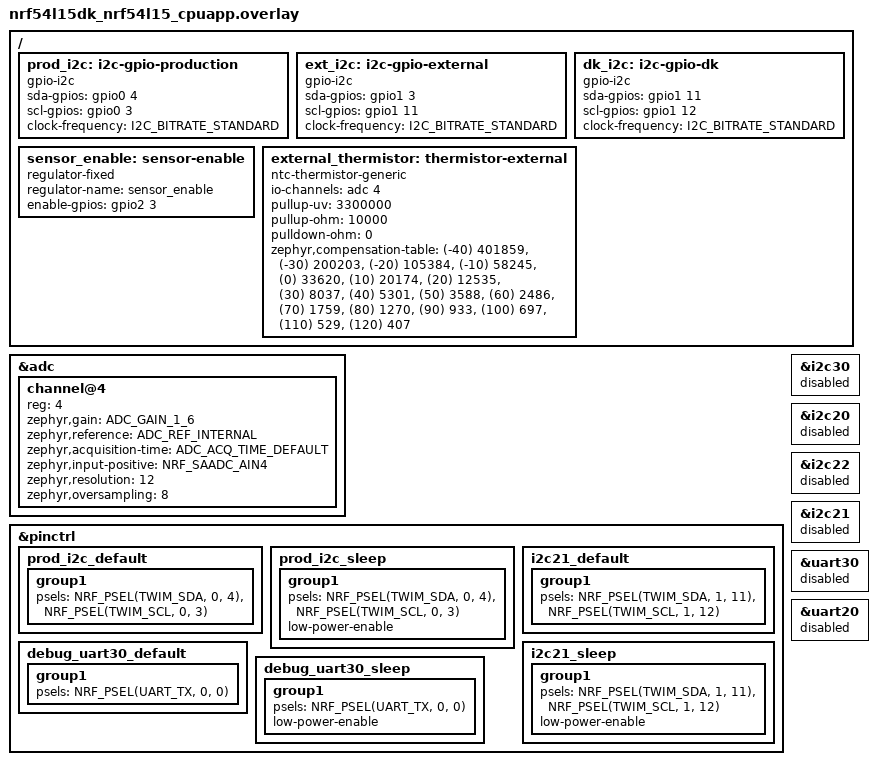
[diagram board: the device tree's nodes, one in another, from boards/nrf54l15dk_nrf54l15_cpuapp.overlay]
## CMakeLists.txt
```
# SPDX-License-Identifier: Apache-2.0

cmake_minimum_required(VERSION 3.20.0)
find_package(Zephyr REQUIRED HINTS $ENV{ZEPHYR_BASE})
project(blinky)

target_sources(app PRIVATE src/main.c)
target_sources(app PRIVATE src/sentry_auth.c)
target_sources(app PRIVATE src/serial30_mux.c)
target_sources_ifdef(CONFIG_BT_RAS_RRSP app PRIVATE src/cs_reflector.c)
```

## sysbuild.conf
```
# Build MCUboot alongside SS1 and create primary/secondary image slots.
SB_CONFIG_BOOTLOADER_MCUBOOT=y
SB_CONFIG_BOOT_SIGNATURE_TYPE_ECDSA_P256=y

# Production signing key. The private key is intentionally gitignored and
# must be provisioned locally/through CI before a production build.
SB_CONFIG_BOOT_SIGNATURE_KEY_FILE="\${APPLICATION_CONFIG_DIR}/keys/ss1_mcuboot_prod_key.pem"
```

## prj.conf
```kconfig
CONFIG_GPIO=y
CONFIG_SENSOR=y

CONFIG_BT=y
CONFIG_BT_PERIPHERAL=y
CONFIG_BT_DEVICE_NAME="Joseph_BLE"
CONFIG_HWINFO=y

# Allow up to 3 simultaneous BLE connections
CONFIG_BT_MAX_CONN=3

CONFIG_PRINTK=y
CONFIG_SERIAL=y
CONFIG_CONSOLE=n
CONFIG_UART_CONSOLE=n
CONFIG_STDOUT_CONSOLE=n
CONFIG_REBOOT=y
CONFIG_NRFX_UARTE=y
CONFIG_NRFX_TWIM=y

# Bluetooth-standard security
CONFIG_BT_SMP=y
CONFIG_BT_BONDABLE=y
CONFIG_BT_MAX_PAIRED=3
CONFIG_BT_KEYS_OVERWRITE_OLDEST=y
CONFIG_BT_GATT_AUTO_SEC_REQ=n

# Let the app accept/reject incoming pairing requests
CONFIG_BT_SMP_APP_PAIRING_ACCEPT=y

# Settings/NVS retain the encryption bond; certificate auth still uses a
# fresh nonce on every connection.
CONFIG_BT_SETTINGS=y
CONFIG_SETTINGS=y
CONFIG_FLASH=y
CONFIG_FLASH_MAP=y
CONFIG_NVS=y

CONFIG_I2C=y
CONFIG_I2C_NRFX=y
CONFIG_I2C_GPIO=y
CONFIG_I2C_GPIO_CLOCK_STRETCHING=y
CONFIG_ADC=y
CONFIG_NTC_THERMISTOR=y

# PSA crypto (nRF54L15 CRACEN). NRF_SECURITY is selected automatically.
CONFIG_NRF_OBERON=y
CONFIG_PSA_WANT_ALG_ECDSA=y
CONFIG_PSA_WANT_ALG_SHA_256=y
CONFIG_PSA_WANT_ECC_SECP_R1_256=y
CONFIG_PSA_WANT_KEY_TYPE_ECC_PUBLIC_KEY=y
CONFIG_PSA_WANT_GENERATE_RANDOM=y

# Bigger ATT MTU so the 204-byte auth response fits in one write.
CONFIG_BT_L2CAP_TX_MTU=247
CONFIG_BT_BUF_ACL_TX_SIZE=251
CONFIG_BT_BUF_ACL_RX_SIZE=251

# SS1 supports three links and RAS can leave several ATT packets queued while
# a departed link is being torn down. Keep response headroom so a replacement
# link can always answer its MTU exchange instead of silently timing out.
CONFIG_BT_ATT_TX_COUNT=12
CONFIG_BT_L2CAP_TX_BUF_COUNT=12
CONFIG_BT_BUF_ACL_TX_COUNT=6

# --- Channel Sounding: RAS Reflector role ---
CONFIG_BT_CTLR_PHY_2M=y
CONFIG_BT_CTLR_DATA_LENGTH_MAX=251
CONFIG_BT_TRANSMIT_POWER_CONTROL=y

# Single-antenna, mode-3-disabled profile (matches Blonky's initiator config)
CONFIG_BT_RAS_MODE_3_SUPPORTED=n
CONFIG_BT_RAS_MAX_ANTENNA_PATHS=1
CONFIG_BT_CTLR_SDC_CS_MAX_ANTENNA_PATHS=1
CONFIG_BT_CTLR_SDC_CS_NUM_ANTENNAS=1
CONFIG_BT_CTLR_SDC_CS_STEP_MODE3=n
CONFIG_BT_CTLR_SDC_CS_ROLE_REFLECTOR_ONLY=y
CONFIG_BT_CTLR_CHANNEL_SOUNDING_TEST=n

CONFIG_BT_CHANNEL_SOUNDING=y
CONFIG_BT_RAS=y
CONFIG_BT_RAS_RRSP=y

# MCUboot + MCUmgr/SMP firmware updates over BLE. Only the image and OS
# management groups are enabled; shell, filesystem and settings erase are not.
CONFIG_BOOTLOADER_MCUBOOT=y
# Keep application-side imgtool metadata aligned with the ECDSA-P256 MCUboot
# child image. ECDSA-P256 selects SHA-256 in MCUboot, so imgtool must emit the
# corresponding SHA-256 image hash TLV.
CONFIG_MCUBOOT_BOOTLOADER_SIGNATURE_TYPE_ED25519=n
CONFIG_MCUBOOT_BOOTLOADER_USES_SHA512=n
CONFIG_MCUBOOT_BOOTLOADER_NO_DOWNGRADE=y
CONFIG_NET_BUF=y
CONFIG_ZCBOR=y
CONFIG_CRC=y
CONFIG_STREAM_FLASH=y
CONFIG_IMG_MANAGER=y
CONFIG_MCUMGR=y
CONFIG_MCUMGR_GRP_IMG=y
CONFIG_MCUMGR_GRP_OS=y
CONFIG_MCUMGR_TRANSPORT_BT=y
# Lab/test transport: image authenticity is still enforced by MCUboot's
# signature. Replace this with an authenticated OTA gate before deployment.
CONFIG_MCUMGR_TRANSPORT_BT_PERM_RW=y
CONFIG_BT_GATT_AUTHORIZATION_CUSTOM=y
CONFIG_MCUMGR_TRANSPORT_BT_CONN_PARAM_CONTROL=y
CONFIG_MCUMGR_TRANSPORT_BT_REASSEMBLY=y
CONFIG_MCUMGR_TRANSPORT_NETBUF_SIZE=1220
CONFIG_MCUMGR_GRP_OS_MCUMGR_PARAMS=y
CONFIG_MCUMGR_TRANSPORT_WORKQUEUE_STACK_SIZE=4608
```

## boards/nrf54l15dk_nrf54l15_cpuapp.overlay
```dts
/*
 * The production PCB places both debug TX and the sensor on P0. UART30 and
 * TWIM30 are the same SERIAL30 block, so keep the reliable hardware UART and
 * use Zephyr's GPIO I2C controller for the low-rate SHT41 bus.
 */
/ {
	prod_i2c: i2c-gpio-production {
		compatible = "gpio-i2c";
		status = "okay";
		#address-cells = <1>;
		#size-cells = <0>;
		sda-gpios = <&gpio0 4 (GPIO_OPEN_DRAIN | GPIO_PULL_UP)>;
		scl-gpios = <&gpio0 3 (GPIO_OPEN_DRAIN | GPIO_PULL_UP)>;
		clock-frequency = <I2C_BITRATE_STANDARD>;
	};

	ext_i2c: i2c-gpio-external {
		compatible = "gpio-i2c";
		status = "okay";
		#address-cells = <1>;
		#size-cells = <0>;
		sda-gpios = <&gpio1 3 (GPIO_OPEN_DRAIN | GPIO_PULL_UP)>;
		scl-gpios = <&gpio1 11 (GPIO_OPEN_DRAIN | GPIO_PULL_UP)>;
		clock-frequency = <I2C_BITRATE_STANDARD>;
	};

	/* GPIO implementation avoids a static TWIM21 claim on P1.11, which is
	 * also the external connector's SCL/thermistor ADC signal. */
	dk_i2c: i2c-gpio-dk {
		compatible = "gpio-i2c";
		status = "okay";
		#address-cells = <1>;
		#size-cells = <0>;
		sda-gpios = <&gpio1 11 (GPIO_OPEN_DRAIN | GPIO_PULL_UP)>;
		scl-gpios = <&gpio1 12 (GPIO_OPEN_DRAIN | GPIO_PULL_UP)>;
		clock-frequency = <I2C_BITRATE_STANDARD>;
	};

	/* Production SS1 switched sensor rail, active-high on P2.03. */
	sensor_enable: sensor-enable {
		compatible = "regulator-fixed";
		regulator-name = "sensor_enable";
		enable-gpios = <&gpio2 3 GPIO_ACTIVE_HIGH>;
	};

	/*
	 * Optional external 10 kOhm/B3950 NTC. The PCB's 10 kOhm pull-up is
	 * already connected to EX_SCL_THERM2 (P1.11/AIN4); the attachment puts
	 * the thermistor between that signal and ground.
	 */
	external_thermistor: thermistor-external {
		compatible = "ntc-thermistor-generic";
		status = "okay";
		io-channels = <&adc 4>;
		pullup-uv = <3300000>;
		pullup-ohm = <10000>;
		pulldown-ohm = <0>;
		zephyr,compensation-table = <(-40) 401859>,
			<(-30) 200203>,
			<(-20) 105384>,
			<(-10) 58245>,
			<(0) 33620>,
			<(10) 20174>,
			<(20) 12535>,
			<(30) 8037>,
			<(40) 5301>,
			<(50) 3588>,
			<(60) 2486>,
			<(70) 1759>,
			<(80) 1270>,
			<(90) 933>,
			<(100) 697>,
			<(110) 529>,
			<(120) 407>;
	};

};

&adc {
	status = "okay";
	#address-cells = <1>;
	#size-cells = <0>;

	channel@4 {
		reg = <4>;
		zephyr,gain = "ADC_GAIN_1_6";
		zephyr,reference = "ADC_REF_INTERNAL";
		zephyr,acquisition-time = <ADC_ACQ_TIME_DEFAULT>;
		zephyr,input-positive = <NRF_SAADC_AIN4>; /* P1.11 */
		zephyr,resolution = <12>;
		zephyr,oversampling = <8>;
	};
};

&pinctrl {
	prod_i2c_default: prod_i2c_default {
		group1 {
			psels = <NRF_PSEL(TWIM_SDA, 0, 4)>,
				<NRF_PSEL(TWIM_SCL, 0, 3)>;
		};
	};

	prod_i2c_sleep: prod_i2c_sleep {
		group1 {
			psels = <NRF_PSEL(TWIM_SDA, 0, 4)>,
				<NRF_PSEL(TWIM_SCL, 0, 3)>;
			low-power-enable;
		};
	};

	i2c21_default: i2c21_default {
		group1 {
			psels = <NRF_PSEL(TWIM_SDA, 1, 11)>,
				<NRF_PSEL(TWIM_SCL, 1, 12)>;
		};
	};

	i2c21_sleep: i2c21_sleep {
		group1 {
			psels = <NRF_PSEL(TWIM_SDA, 1, 11)>,
				<NRF_PSEL(TWIM_SCL, 1, 12)>;
			low-power-enable;
		};
	};

	debug_uart30_default: debug_uart30_default {
		group1 {
			psels = <NRF_PSEL(UART_TX, 0, 0)>;
		};
	};

	debug_uart30_sleep: debug_uart30_sleep {
		group1 {
			psels = <NRF_PSEL(UART_TX, 0, 0)>;
			low-power-enable;
		};
	};

};

/*
 * Production SS1 I2C: SDA P0.04, SCL P0.03.
 *
 * TWIM20/21/22 are physically restricted to GPIO port P1 on nRF54L15.
 * TWIM30 is the hardware controller that can reach GPIO port P0.
 */
&i2c30 {
	status = "disabled";
};

&i2c20 {
	status = "disabled";
};

&i2c22 {
	status = "disabled";
};

/* DK I2C: SDA P1.11, SCL P1.12. */
&i2c21 {
	status = "disabled";
};

&uart30 {
	status = "disabled";
};

&uart20 {
	status = "disabled";
};
```

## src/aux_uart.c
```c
/*
 * SPDX-License-Identifier: Apache-2.0
 */

#include <stdbool.h>
#include <stddef.h>
#include <stdint.h>
#include <string.h>

#include <zephyr/device.h>
#include <zephyr/drivers/uart.h>
#include <zephyr/sys/printk.h>
#include <zephyr/sys/util.h>
#include <zephyr/bluetooth/bluetooth.h>
#include <zephyr/bluetooth/addr.h>

#include "aux_uart.h"

#define AUX_UART_NODE DT_NODELABEL(uart30)

#define AUX_PAN_LEN  4
#define AUX_ID_LEN   2
#define AUX_MSG_LEN  9   /* both TSSA... and HSSA... messages are 9 chars */

static const struct device *aux_uart_dev = DEVICE_DT_GET(AUX_UART_NODE);
static bool aux_uart_ready;

static char aux_pan_id[AUX_PAN_LEN + 1] = "0000";
static char aux_unit_id[AUX_ID_LEN + 1] = "00";

static uint8_t aux_seq;

static const char aux_status_msg[AUX_MSG_LEN] = {
	'S', 'S', '3', '6', '1', '#', 'H', '1', 'W',
};

static void aux_uart_write(const char *buf, size_t len)
{
	for (size_t i = 0; i < len; i++) {
		uart_poll_out(aux_uart_dev, buf[i]);
	}
}

void aux_uart_init_check(void)
{
	if (!device_is_ready(aux_uart_dev)) {
		aux_uart_ready = false;
		printk("AUX UART (uart30) is not ready. Packet output disabled.\n");
		return;
	}

	aux_uart_ready = true;

	printk("AUX UART ready: %s (P0.00 TX / P0.01 RX / P0.02 RTS / P0.03 CTS)\n",
	       aux_uart_dev->name);
}

void aux_uart_load_identity(void)
{
	bt_addr_le_t addrs[CONFIG_BT_ID_MAX];
	size_t count = ARRAY_SIZE(addrs);
	char hex[2 * 6 + 1];

	bt_id_get(addrs, &count);

	if (count == 0) {
		printk("AUX UART: no BT identity address yet - keeping placeholder PAN=%s ID=%s\n",
		       aux_pan_id, aux_unit_id);
		return;
	}

	/*
	 * bt_addr_le_t stores the 6-byte MAC little-endian (val[0] = LSB).
	 * Rebuild it MSB-first (the order a MAC is conventionally written
	 * in, e.g. as bt_addr_le_to_str prints it) before slicing hex
	 * characters out of it. This is the genuine identity address -
	 * bt_id_get() returns it even when LE Privacy is enabled and a
	 * rotating RPA is what's actually broadcast over the air.
	 */
	snprintk(hex, sizeof(hex), "%02X%02X%02X%02X%02X%02X",
		 addrs[0].a.val[5], addrs[0].a.val[4], addrs[0].a.val[3],
		 addrs[0].a.val[2], addrs[0].a.val[1], addrs[0].a.val[0]);

	memcpy(aux_pan_id, hex, AUX_PAN_LEN);
	aux_pan_id[AUX_PAN_LEN] = '\0';
	memcpy(aux_unit_id, hex + AUX_PAN_LEN, AUX_ID_LEN);
	aux_unit_id[AUX_ID_LEN] = '\0';

	printk("AUX UART packet identity: PAN=%s ID=%s (from BT MAC %s)\n",
	       aux_pan_id, aux_unit_id, hex);
}

/* "TSSA" <sign> <tens><units> '.' <decimal> -> 9 chars, no NUL. */
static void format_temp_msg(char out[AUX_MSG_LEN], int16_t temp_cdeg)
{
	int32_t temp_deci = (temp_cdeg >= 0) ? (temp_cdeg + 5) / 10 : (temp_cdeg - 5) / 10;
	char sign = (temp_deci < 0) ? '-' : '+';
	int32_t whole = (temp_deci < 0) ? -temp_deci : temp_deci;
	int32_t frac = whole % 10;

	whole /= 10;
	if (whole > 99) {
		whole = 99; /* saturate: format is fixed at 2 digits */
	}

	snprintk(out, AUX_MSG_LEN + 1, "TSSA%c%02d.%d", sign, (int)whole, (int)frac);
}

/* "HSSA" <tens><units> '.' <decimal> <pad '-'> -> 9 chars, no NUL, no sign. */
static void format_hum_msg(char out[AUX_MSG_LEN], uint16_t hum_cpercent)
{
	uint32_t deci = (hum_cpercent + 5) / 10;
	int32_t frac = deci % 10;
	int32_t whole = deci / 10;
	int len;

	if (whole > 99) {
		whole = 99;
	}

	len = snprintk(out, AUX_MSG_LEN, "HSSA%02d.%d", (int)whole, (int)frac);
	while (len < AUX_MSG_LEN) {
		out[len++] = '-';
	}
}

/*
 * m <PAN><ID> d <data...> r -<RSSI 000> s <seq 3 digits> CR
 * CR (0x0D) only - no trailing LF, per the reference packet format.
 */
/* Envelope overhead (everything except the data section):
 * 'm' + PAN(4) + ID(2) + 'd' + 'r' + '-' + RSSI(3) + 's' + seq(3) + CR(1) = 19
 */
#define AUX_PACKET_OVERHEAD 19

static void send_packet(const char *data, size_t data_len)
{
	char pkt[AUX_PACKET_OVERHEAD + AUX_MSG_LEN];
	size_t len = 0;

	pkt[len++] = 'm';
	memcpy(&pkt[len], aux_pan_id, AUX_PAN_LEN);
	len += AUX_PAN_LEN;
	memcpy(&pkt[len], aux_unit_id, AUX_ID_LEN);
	len += AUX_ID_LEN;
	pkt[len++] = 'd';
	memcpy(&pkt[len], data, data_len);
	len += data_len;
	pkt[len++] = 'r';
	pkt[len++] = '-';
	memcpy(&pkt[len], "000", 3);
	len += 3;
	pkt[len++] = 's';
	pkt[len++] = '0' + (aux_seq / 100) % 10;
	pkt[len++] = '0' + (aux_seq / 10) % 10;
	pkt[len++] = '0' + (aux_seq % 10);
	pkt[len++] = '\r';

	aux_uart_write(pkt, len);
}

static void advance_sequence(void)
{
	aux_seq++;

	if (aux_seq == 0) {
		/* Rolled over 255 -> 0: send the status message using the
		 * wrapped value, then move past it before normal data resumes.
		 */
		send_packet(aux_status_msg, AUX_MSG_LEN);
		aux_seq++;
	}
}

void aux_uart_send_temp_humidity(int16_t temp_cdeg, uint16_t hum_cpercent)
{
	char msg[AUX_MSG_LEN];

	if (!aux_uart_ready) {
		return;
	}

	/* One packet per value - each is its own transmission and consumes
	 * its own sequence number. */
	format_temp_msg(msg, temp_cdeg);
	send_packet(msg, AUX_MSG_LEN);
	advance_sequence();

	format_hum_msg(msg, hum_cpercent);
	send_packet(msg, AUX_MSG_LEN);
	advance_sequence();
}
```

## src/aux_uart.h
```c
/*
 * SPDX-License-Identifier: Apache-2.0
 *
 * Auxiliary UART (uart30) - wired sensor-bridge packet output.
 *
 * UART instance on P0.00(TX)/P0.01(RX)/P0.02(RTS)/P0.03(CTS). On the
 * production board it is shared with the printk/debug console because this
 * is the only exposed serial output. Feeds a TTL serial converter, not SS2.
 *
 * Implements the reference "sensor bridge unit" packet format:
 *   m <PAN 4ch> <unit ID 2ch> d <data> r -<RSSI 3ch> s <seq 3ch> CR
 * with per-reading messages:
 *   Temperature: "TSSA" <sign> <tens><units> '.' <decimal>       (9 chars)
 *   Humidity:    "HSSA" <tens><units> '.' <decimal> <pad '-'>    (9 chars)
 * One packet per value: a temperature reading and a humidity reading are
 * sent as two separate packets, each with its own sequence number. RSSI is
 * always "000" (wired, no radio). The sequence counter is a rolling 1-byte
 * counter, shared across both packet types; on wraparound (255 -> 0) a
 * status message ("SS361#H1W", hardware char 'W' = wired sensor) is sent
 * using the wrapped value before normal data resumes.
 *
 * PAN ID / unit ID are derived from this device's real BLE identity
 * address (via bt_id_get(), which always returns the genuine, fixed
 * address - not a rotating LE Privacy/RPA address): the first 4 hex
 * characters of the MAC (in conventional MSB-first display order) become
 * the PAN ID, the next 2 become the unit ID.
 */

#ifndef AUX_UART_H_
#define AUX_UART_H_

#include <stdint.h>

/* Call once from main(), alongside sht3x_init_check(). Readies the uart30
 * device only; does not touch BLE.
 */
void aux_uart_init_check(void);

/* Call once from main(), after bt_enable() and settings_load() have both
 * completed, so the real identity address (and any settings-restored
 * address) is available. Derives the PAN ID / unit ID from it.
 */
void aux_uart_load_identity(void);

/* Send two packets, temperature then humidity. No-op if uart30 isn't
 * ready. temp_cdeg: centi-degrees C (2534 = 25.34 C). hum_cpercent:
 * centi-%RH.
 */
void aux_uart_send_temp_humidity(int16_t temp_cdeg, uint16_t hum_cpercent);

#endif /* AUX_UART_H_ */
```

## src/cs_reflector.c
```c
/*
 * SPDX-License-Identifier: Apache-2.0
 */

#include <zephyr/kernel.h>
#include <zephyr/sys/printk.h>
#include <zephyr/sys/byteorder.h>
#include <zephyr/bluetooth/conn.h>
#include <zephyr/bluetooth/cs.h>
#include <bluetooth/services/ras.h>

#include "cs_reflector.h"

static void remote_capabilities_cb(struct bt_conn *conn, uint8_t status,
				   struct bt_conn_le_cs_capabilities *params)
{
	ARG_UNUSED(conn);
	ARG_UNUSED(params);

	if (status != BT_HCI_ERR_SUCCESS) {
		printk("CS reflector: capability exchange failed (status 0x%02x)\n", status);
	}
}

static void config_create_cb(struct bt_conn *conn, uint8_t status,
			     struct bt_conn_le_cs_config *config)
{
	int err;

	ARG_UNUSED(config);

	if (status != BT_HCI_ERR_SUCCESS) {
		printk("CS reflector: config creation failed (status 0x%02x)\n", status);
		return;
	}

	const struct bt_le_cs_set_procedure_parameters_param procedure_params = {
		.config_id = 0,
		.max_procedure_len = 1000,
		.min_procedure_interval = 1,
		.max_procedure_interval = 100,
		.max_procedure_count = 0,
		.min_subevent_len = 10000,
		.max_subevent_len = 75000,
		.tone_antenna_config_selection = BT_LE_CS_TONE_ANTENNA_CONFIGURATION_A1_B1,
		.phy = BT_LE_CS_PROCEDURE_PHY_2M,
		.tx_power_delta = 0x80,
		.preferred_peer_antenna = BT_LE_CS_PROCEDURE_PREFERRED_PEER_ANTENNA_1,
		.snr_control_initiator = BT_LE_CS_SNR_CONTROL_NOT_USED,
		.snr_control_reflector = BT_LE_CS_SNR_CONTROL_NOT_USED,
	};

	err = bt_le_cs_set_procedure_parameters(conn, &procedure_params);
	if (err) {
		printk("CS reflector: failed to set procedure parameters (err %d)\n", err);
	}
}

static void security_enable_cb(struct bt_conn *conn, uint8_t status)
{
	ARG_UNUSED(conn);

	if (status != BT_HCI_ERR_SUCCESS) {
		printk("CS reflector: security enable failed (status 0x%02x)\n", status);
	}
}

static void procedure_enable_cb(struct bt_conn *conn, uint8_t status,
				struct bt_conn_le_cs_procedure_enable_complete *params)
{
	ARG_UNUSED(conn);

	if (status != BT_HCI_ERR_SUCCESS) {
		printk("CS reflector: procedure enable failed (status 0x%02x)\n", status);
		return;
	}

	printk("CS reflector: procedures %s\n", params->state ? "enabled" : "disabled");
}

BT_CONN_CB_DEFINE(cs_reflector_conn_cb) = {
	.le_cs_read_remote_capabilities_complete = remote_capabilities_cb,
	.le_cs_config_complete = config_create_cb,
	.le_cs_security_enable_complete = security_enable_cb,
	.le_cs_procedure_enable_complete = procedure_enable_cb,
};

void cs_reflector_conn_ready(struct bt_conn *conn)
{
	int err;

	const struct bt_le_cs_set_default_settings_param default_settings = {
		.enable_initiator_role = false,
		.enable_reflector_role = true,
		.cs_sync_antenna_selection = BT_LE_CS_ANTENNA_SELECTION_OPT_REPETITIVE,
		.max_tx_power = BT_HCI_OP_LE_CS_MAX_MAX_TX_POWER,
	};

	err = bt_le_cs_set_default_settings(conn, &default_settings);
	if (err) {
		printk("CS reflector: failed to set default settings (err %d)\n", err);
		return;
	}

	printk("CS reflector: ready for ranging on this connection\n");
}
```

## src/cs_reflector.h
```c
/*
 * SPDX-License-Identifier: Apache-2.0
 *
 * Bluetooth Channel Sounding - Ranging Responder (reflector) role.
 *
 * Lets a connected, encrypted peer (e.g. Blonky/SS2) run CS ranging against
 * this device and read back its own distance estimate. The Ranging Service
 * GATT server itself is provided automatically by the BT_RAS_RRSP library
 * once CONFIG_BT_RAS_RRSP=y - this module only reacts to the CS connection
 * callbacks needed to accept the peer's ranging configuration.
 */

#ifndef CS_REFLECTOR_H_
#define CS_REFLECTOR_H_

#include <zephyr/bluetooth/conn.h>

/* Call after a connection reaches BT_SECURITY_L2 and passes certificate auth.
 * Enables the reflector role for that connection; the peer drives the rest
 * of the CS setup.
 * Compiles to a no-op when Channel Sounding is disabled.
 */
#ifdef CONFIG_BT_RAS_RRSP
void cs_reflector_conn_ready(struct bt_conn *conn);
#else
static inline void cs_reflector_conn_ready(struct bt_conn *conn)
{
	(void)conn;
}
#endif

#endif /* CS_REFLECTOR_H_ */
```

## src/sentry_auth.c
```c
/*
 * SPDX-License-Identifier: Apache-2.0
 *
 * Smart Sentry certificate-based device pre-approval - implementation.
 *
 * GATT auth service:
 *   Challenge characteristic (READ, encrypted): 32-byte per-connection nonce.
 *   Response  characteristic (WRITE, encrypted): client writes
 *       [ cert (140) || ecdsa_sign(nonce) (64) ] = 204 bytes.
 *
 * On a valid response the connection is flagged authenticated. If a
 * connection has not authenticated within SENTRY_AUTH_TIMEOUT_MS it is
 * disconnected.
 */

#include "sentry_auth.h"
#include "cs_reflector.h"

#include <string.h>
#include <zephyr/kernel.h>
#include <zephyr/sys/printk.h>
#include <zephyr/bluetooth/bluetooth.h>
#include <zephyr/bluetooth/gatt.h>
#include <zephyr/bluetooth/uuid.h>
#include <zephyr/bluetooth/hci.h>

#include <psa/crypto.h>

/* ---------------- Root CA public key ----------------
 *
 * Paste the output of `python3 provision.py firmware-header` here.
 * This is the ONLY trust anchor on the device. The CA *private* key never
 * touches the firmware.
 *
 * The 64 bytes below are a PLACEHOLDER - replace them or auth will reject
 * every client.
 */
static const uint8_t root_ca_pubkey[64] = {
	0xcb, 0x3b, 0x9a, 0x45, 0x19, 0x49, 0xb7, 0xc2,
	0x50, 0x51, 0x34, 0xa7, 0x37, 0x62, 0x70, 0x96,
	0x64, 0xb7, 0x9d, 0x97, 0x77, 0x65, 0x0d, 0xb3,
	0xb1, 0x8f, 0xc6, 0x2b, 0x91, 0x5b, 0x30, 0x75,
	0xdf, 0x38, 0xf4, 0xbc, 0x73, 0x49, 0xfe, 0x9b,
	0x43, 0x6d, 0xd9, 0x71, 0x0c, 0xe8, 0x26, 0x4c,
	0x8d, 0x4a, 0x80, 0x94, 0x07, 0x4a, 0x51, 0xc0,
	0x0c, 0x9c, 0xbc, 0x34, 0x98, 0x95, 0xb1, 0x21,
};

/* ---------------- Custom UUIDs ----------------
 * Auth service:   7e8f00a0-...
 * Challenge char: 7e8f00a1-...
 * Response char:  7e8f00a2-...
 */
#define BT_UUID_SENTRY_AUTH_SVC_VAL \
	BT_UUID_128_ENCODE(0x7e8f00a0, 0x1111, 0x2222, 0x3333, 0x123456789abc)
#define BT_UUID_SENTRY_AUTH_CHALLENGE_VAL \
	BT_UUID_128_ENCODE(0x7e8f00a1, 0x1111, 0x2222, 0x3333, 0x123456789abc)
#define BT_UUID_SENTRY_AUTH_RESPONSE_VAL \
	BT_UUID_128_ENCODE(0x7e8f00a2, 0x1111, 0x2222, 0x3333, 0x123456789abc)

static struct bt_uuid_128 auth_svc_uuid =
	BT_UUID_INIT_128(BT_UUID_SENTRY_AUTH_SVC_VAL);
static struct bt_uuid_128 auth_challenge_uuid =
	BT_UUID_INIT_128(BT_UUID_SENTRY_AUTH_CHALLENGE_VAL);
static struct bt_uuid_128 auth_response_uuid =
	BT_UUID_INIT_128(BT_UUID_SENTRY_AUTH_RESPONSE_VAL);

/* ---------------- Per-connection auth state ---------------- */

struct auth_slot {
	struct bt_conn *conn;
	uint8_t nonce[SENTRY_NONCE_LEN];
	bool nonce_valid;
	bool authenticated;
	struct k_work_delayable timeout;
};

static struct auth_slot slots[CONFIG_BT_MAX_CONN];

static struct auth_slot *slot_for(struct bt_conn *conn)
{
	for (int i = 0; i < CONFIG_BT_MAX_CONN; i++) {
		if (slots[i].conn == conn) {
			return &slots[i];
		}
	}
	return NULL;
}

static struct auth_slot *slot_alloc(struct bt_conn *conn)
{
	for (int i = 0; i < CONFIG_BT_MAX_CONN; i++) {
		if (slots[i].conn == NULL) {
			slots[i].conn = conn;
			slots[i].nonce_valid = false;
			slots[i].authenticated = false;
			return &slots[i];
		}
	}
	return NULL;
}

/* ---------------- ECDSA-P256 verify via PSA ----------------
 *
 * Mirrors device_sim.py: verify(pub_xy, message, raw_r||s).
 * PSA wants the public key as an uncompressed point (0x04 || X || Y).
 */
static bool ecdsa_p256_verify(const uint8_t pub_xy[64],
			      const uint8_t *msg, size_t msg_len,
			      const uint8_t sig[SENTRY_SIG_LEN])
{
	psa_status_t status;
	psa_key_id_t key_id;
	psa_key_attributes_t attr = PSA_KEY_ATTRIBUTES_INIT;
	uint8_t point[65];

	point[0] = 0x04;
	memcpy(&point[1], pub_xy, 64);

	psa_set_key_usage_flags(&attr, PSA_KEY_USAGE_VERIFY_MESSAGE);
	psa_set_key_algorithm(&attr, PSA_ALG_ECDSA(PSA_ALG_SHA_256));
	psa_set_key_type(&attr,
			 PSA_KEY_TYPE_ECC_PUBLIC_KEY(PSA_ECC_FAMILY_SECP_R1));
	psa_set_key_bits(&attr, 256);

	status = psa_import_key(&attr, point, sizeof(point), &key_id);
	if (status != PSA_SUCCESS) {
		printk("psa_import_key failed: %d\n", (int)status);
		return false;
	}

	status = psa_verify_message(key_id, PSA_ALG_ECDSA(PSA_ALG_SHA_256),
				    msg, msg_len, sig, SENTRY_SIG_LEN);

	psa_destroy_key(key_id);

	return status == PSA_SUCCESS;
}

/* ---------------- Response verification ---------------- */

static bool verify_response(struct auth_slot *slot,
			    const uint8_t *resp, uint16_t len)
{
	const uint8_t *cert;
	const uint8_t *nonce_sig;
	const uint8_t *body;
	const uint8_t *ca_sig;
	const uint8_t *client_pub;

	if (len != SENTRY_RESPONSE_LEN) {
		printk("Auth: bad response length %u (want %u)\n",
		       len, SENTRY_RESPONSE_LEN);
		return false;
	}

	if (!slot->nonce_valid) {
		printk("Auth: no valid nonce for this connection\n");
		return false;
	}

	cert = resp;
	nonce_sig = resp + SENTRY_CERT_TOTAL_LEN;
	body = cert;
	ca_sig = cert + SENTRY_CERT_BODY_LEN;
	client_pub = body + SENTRY_CERT_OFF_PUBKEY;

	if (body[0] != SENTRY_CERT_VERSION) {
		printk("Auth: unsupported cert version %u\n", body[0]);
		return false;
	}

	/* 1. Is this cert genuinely issued by our CA? */
	if (!ecdsa_p256_verify(root_ca_pubkey, body, SENTRY_CERT_BODY_LEN,
			       ca_sig)) {
		printk("Auth: CA signature invalid - cert not ours\n");
		return false;
	}

	/* 2. Does the peer actually hold the cert's private key? */
	if (!ecdsa_p256_verify(client_pub, slot->nonce, SENTRY_NONCE_LEN,
			       nonce_sig)) {
		printk("Auth: nonce signature invalid - no private key\n");
		return false;
	}

	/*
	 * TODO (revocation / expiry):
	 *   - not_after at body + SENTRY_CERT_OFF_NOTAFTER, needs a trusted
	 *     time source to enforce.
	 *   - client_id at body + SENTRY_CERT_OFF_ID: check against an on-device
	 *     allowlist/denylist here to support revocation.
	 */
	return true;
}

/* ---------------- Auth timeout ---------------- */

static void auth_timeout(struct k_work *work)
{
	struct k_work_delayable *dw = k_work_delayable_from_work(work);
	struct auth_slot *slot = CONTAINER_OF(dw, struct auth_slot, timeout);

	if (slot->conn && !slot->authenticated) {
		printk("Auth: timeout, disconnecting unauthenticated peer\n");
		bt_conn_disconnect(slot->conn,
				   BT_HCI_ERR_REMOTE_USER_TERM_CONN);
	}
}

/* ---------------- GATT callbacks ---------------- */

static ssize_t read_challenge_cb(struct bt_conn *conn,
				 const struct bt_gatt_attr *attr,
				 void *buf, uint16_t len, uint16_t offset)
{
	struct auth_slot *slot = slot_for(conn);

	if (!slot || !slot->nonce_valid) {
		return BT_GATT_ERR(BT_ATT_ERR_UNLIKELY);
	}

	return bt_gatt_attr_read(conn, attr, buf, len, offset,
				 slot->nonce, SENTRY_NONCE_LEN);
}

static ssize_t write_response_cb(struct bt_conn *conn,
				 const struct bt_gatt_attr *attr,
				 const void *buf, uint16_t len,
				 uint16_t offset, uint8_t flags)
{
	struct auth_slot *slot = slot_for(conn);

	ARG_UNUSED(attr);
	ARG_UNUSED(flags);

	if (offset != 0) {
		return BT_GATT_ERR(BT_ATT_ERR_INVALID_OFFSET);
	}
	if (!slot) {
		return BT_GATT_ERR(BT_ATT_ERR_UNLIKELY);
	}

	if (verify_response(slot, buf, len)) {
		slot->authenticated = true;
		slot->nonce_valid = false; /* one-shot: consume the nonce */
		k_work_cancel_delayable(&slot->timeout);
		printk("Auth: connection AUTHENTICATED\n");
		/* Do not start controller channel-sounding setup until the GATT
		 * certificate exchange has proved this peer. This also keeps CS HCI
		 * traffic out of the reconnect's critical ATT setup window. */
		cs_reflector_conn_ready(conn);
	} else {
		printk("Auth: verification FAILED, disconnecting\n");
		bt_conn_disconnect(conn, BT_HCI_ERR_AUTH_FAIL);
	}

	return len;
}

BT_GATT_SERVICE_DEFINE(sentry_auth_svc,
	BT_GATT_PRIMARY_SERVICE(&auth_svc_uuid),

	BT_GATT_CHARACTERISTIC(&auth_challenge_uuid.uuid,
			       BT_GATT_CHRC_READ,
			       BT_GATT_PERM_READ_ENCRYPT,
			       read_challenge_cb, NULL, NULL),
	BT_GATT_CUD("Auth Challenge (nonce)", BT_GATT_PERM_READ),

	BT_GATT_CHARACTERISTIC(&auth_response_uuid.uuid,
			       BT_GATT_CHRC_WRITE,
			       BT_GATT_PERM_WRITE_ENCRYPT,
			       NULL, write_response_cb, NULL),
	BT_GATT_CUD("Auth Response (cert + nonce sig)", BT_GATT_PERM_READ),
);

/* ---------------- Public API ---------------- */

int sentry_auth_init(void)
{
	psa_status_t status = psa_crypto_init();

	if (status != PSA_SUCCESS) {
		printk("psa_crypto_init failed: %d\n", (int)status);
		return -1;
	}

	for (int i = 0; i < CONFIG_BT_MAX_CONN; i++) {
		k_work_init_delayable(&slots[i].timeout, auth_timeout);
	}

	printk("Sentry auth ready (cert-based pre-approval)\n");
	return 0;
}

void sentry_auth_conn_added(struct bt_conn *conn)
{
	struct auth_slot *slot = slot_alloc(conn);
	psa_status_t status;

	if (!slot) {
		printk("Auth: no free auth slot\n");
		return;
	}

	status = psa_generate_random(slot->nonce, SENTRY_NONCE_LEN);
	if (status != PSA_SUCCESS) {
		printk("Auth: nonce generation failed: %d\n", (int)status);
		slot->nonce_valid = false;
		bt_conn_disconnect(conn, BT_HCI_ERR_UNSPECIFIED);
		return;
	}

	slot->nonce_valid = true;
	slot->authenticated = false;

	k_work_reschedule(&slot->timeout, K_MSEC(SENTRY_AUTH_TIMEOUT_MS));
	printk("Auth: fresh nonce issued, %d ms to authenticate\n",
	       SENTRY_AUTH_TIMEOUT_MS);
}

void sentry_auth_conn_removed(struct bt_conn *conn)
{
	struct auth_slot *slot = slot_for(conn);

	if (!slot) {
		return;
	}

	k_work_cancel_delayable(&slot->timeout);
	memset(slot->nonce, 0, SENTRY_NONCE_LEN);
	slot->nonce_valid = false;
	slot->authenticated = false;
	slot->conn = NULL;
}

bool sentry_auth_is_authenticated(struct bt_conn *conn)
{
	struct auth_slot *slot = slot_for(conn);

	return slot && slot->authenticated;
}
```

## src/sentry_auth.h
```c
/*
 * SPDX-License-Identifier: Apache-2.0
 *
 * Smart Sentry certificate-based device pre-approval.
 *
 * Layered on top of the existing LESC-encrypted link:
 *   - LESC (Just Works) gives you an ENCRYPTED transport (unchanged).
 *   - This module adds an application-layer AUTHENTICATION step over that
 *     encrypted link: the client must present a certificate signed by the
 *     company root CA, and prove it holds the matching private key by
 *     signing a per-connection random nonce.
 *
 * Sensitive characteristics stay locked until sentry_auth_is_authenticated()
 * returns true for that connection.
 */

#ifndef SENTRY_AUTH_H_
#define SENTRY_AUTH_H_

#include <stdbool.h>
#include <zephyr/bluetooth/conn.h>

/* Wire format - MUST stay byte-for-byte identical to protocol.py */
#define SENTRY_CERT_VERSION     1
#define SENTRY_CERT_BODY_LEN    76   /* version(1)+rsv(3)+id(4)+not_after(4)+pubkey(64) */
#define SENTRY_SIG_LEN          64   /* raw r||s, P-256 */
#define SENTRY_CERT_TOTAL_LEN   (SENTRY_CERT_BODY_LEN + SENTRY_SIG_LEN)   /* 140 */
#define SENTRY_NONCE_LEN        32
#define SENTRY_RESPONSE_LEN     (SENTRY_CERT_TOTAL_LEN + SENTRY_SIG_LEN)  /* 204 */

/* Offsets inside the cert body */
#define SENTRY_CERT_OFF_ID        4
#define SENTRY_CERT_OFF_NOTAFTER  8
#define SENTRY_CERT_OFF_PUBKEY    12

/* Seconds a fresh connection has to authenticate before it is dropped. */
#define SENTRY_AUTH_TIMEOUT_MS    10000

/* Call once after bt_enable(). Initialises PSA crypto. Returns 0 on success. */
int sentry_auth_init(void);

/* Call from your connected() callback (after the link is up). */
void sentry_auth_conn_added(struct bt_conn *conn);

/* Call from your disconnected() callback. */
void sentry_auth_conn_removed(struct bt_conn *conn);

/* Gate check for sensitive reads/writes/notifies. */
bool sentry_auth_is_authenticated(struct bt_conn *conn);

#endif /* SENTRY_AUTH_H_ */
```

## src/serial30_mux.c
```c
#include "serial30_mux.h"

#include <nrfx_twim.h>
#include <nrfx_uarte.h>
#include <hal/nrf_gpio.h>

static nrfx_twim_t twim30 = NRFX_TWIM_INSTANCE(30);
static nrfx_uarte_t uarte30 = NRFX_UARTE_INSTANCE(30);

int serial30_uart_init(void)
{
	nrfx_uarte_config_t config = NRFX_UARTE_DEFAULT_CONFIG(
		NRF_GPIO_PIN_MAP(0, 0), NRF_UARTE_PSEL_DISCONNECTED);

	return nrfx_uarte_init(&uarte30, &config, NULL);
}

int serial30_uart_putc(int c)
{
	uint8_t byte = (uint8_t)c;
	return nrfx_uarte_tx(&uarte30, &byte, 1, 0) == 0 ? c : -1;
}

int serial30_twim_init(void)
{
	nrfx_twim_config_t config = NRFX_TWIM_DEFAULT_CONFIG(
		NRF_GPIO_PIN_MAP(0, 3), NRF_GPIO_PIN_MAP(0, 4));
	int err = nrfx_twim_init(&twim30, &config, NULL, NULL);

	if (err == 0) {
		nrfx_twim_enable(&twim30);
	}
	return err;
}

int serial30_twim_write(uint16_t address, const uint8_t *data, size_t length)
{
	nrfx_twim_xfer_desc_t transfer = NRFX_TWIM_XFER_DESC_TX(
		address, (uint8_t *)data, length);
	return nrfx_twim_xfer(&twim30, &transfer, 0);
}

int serial30_twim_read(uint16_t address, uint8_t *data, size_t length)
{
	nrfx_twim_xfer_desc_t transfer = NRFX_TWIM_XFER_DESC_RX(
		address, data, length);
	return nrfx_twim_xfer(&twim30, &transfer, 0);
}
```

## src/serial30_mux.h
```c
#ifndef SERIAL30_MUX_H_
#define SERIAL30_MUX_H_

#include <stddef.h>
#include <stdint.h>

int serial30_uart_init(void);
int serial30_uart_putc(int c);
int serial30_twim_init(void);
int serial30_twim_write(uint16_t address, const uint8_t *data, size_t length);
int serial30_twim_read(uint16_t address, uint8_t *data, size_t length);

#endif
```
